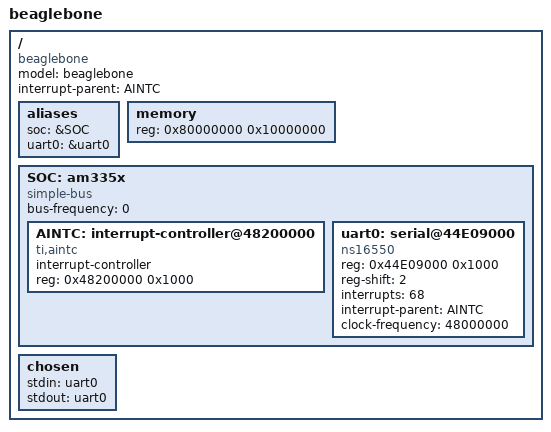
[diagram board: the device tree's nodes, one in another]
/*-
 * Copyright (c) 2012 The FreeBSD Foundation
 * All rights reserved.
 *
 * Developed by Damjan Marion <damjan.marion@gmail.com>
 *
 * Redistribution and use in source and binary forms, with or without
 * modification, are permitted provided that the following conditions
 * are met:
 * 1. Redistributions of source code must retain the above copyright
 *    notice, this list of conditions and the following disclaimer.
 * 2. Redistributions in binary form must reproduce the above copyright
 *    notice, this list of conditions and the following disclaimer in the
 *    documentation and/or other materials provided with the distribution.
 *
 * THIS SOFTWARE IS PROVIDED BY THE AUTHOR AND CONTRIBUTORS ``AS IS'' AND
 * ANY EXPRESS OR IMPLIED WARRANTIES, INCLUDING, BUT NOT LIMITED TO, THE
 * IMPLIED WARRANTIES OF MERCHANTABILITY AND FITNESS FOR A PARTICULAR PURPOSE
 * ARE DISCLAIMED. IN NO EVENT SHALL THE AUTHOR OR CONTRIBUTORS BE LIABLE
 * FOR ANY DIRECT, INDIRECT, INCIDENTAL, SPECIAL, EXEMPLARY, OR CONSEQUENTIAL
 * DAMAGES (INCLUDING, BUT NOT LIMITED TO, PROCUREMENT OF SUBSTITUTE GOODS
 * OR SERVICES; LOSS OF USE, DATA, OR PROFITS; OR BUSINESS INTERRUPTION)
 * HOWEVER CAUSED AND ON ANY THEORY OF LIABILITY, WHETHER IN CONTRACT, STRICT
 * LIABILITY, OR TORT (INCLUDING NEGLIGENCE OR OTHERWISE) ARISING IN ANY WAY
 * OUT OF THE USE OF THIS SOFTWARE, EVEN IF ADVISED OF THE POSSIBILITY OF
 * SUCH DAMAGE.
 */

/dts-v1/;

/ {
	model = "beaglebone";
	compatible = "beaglebone", "ti,am335x";
	#address-cells = <1>;
	#size-cells = <1>;

	interrupt-parent = <&AINTC>;

	aliases {
		soc = &SOC;
		uart0 = &uart0;
	};

	memory {
		device_type = "memory";
		reg = < 0x80000000 0x10000000 >;	/* 256MB RAM */
	};

	SOC: am335x {
		#address-cells = <1>;
		#size-cells = <1>;
		compatible = "simple-bus";
		ranges;
		bus-frequency = <0>;

		AINTC: interrupt-controller@48200000 {
			compatible = "ti,aintc";
			interrupt-controller;
			#address-cells = <0>;
			#interrupt-cells = <1>;
			reg =	< 0x48200000 0x1000 >;
		};

		uart0: serial@44E09000 {
			compatible = "ns16550";
			reg = <0x44E09000 0x1000>;
			reg-shift = <2>;
			interrupts = < 68 >;
			interrupt-parent = <&AINTC>;
			clock-frequency = < 48000000 >; /* FIXME */
		};
	};

	chosen {
		stdin = "uart0";
		stdout = "uart0";
	};
};
